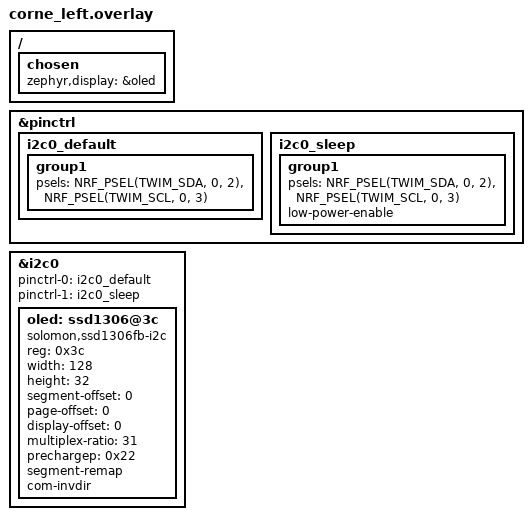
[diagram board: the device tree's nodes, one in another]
/ {
  chosen { zephyr,display = &oled; };
};

&pinctrl {
  i2c0_default: i2c0_default {
    group1 { psels = <NRF_PSEL(TWIM_SDA, 0, 2)>, <NRF_PSEL(TWIM_SCL, 0, 3)>; };
  };
  i2c0_sleep: i2c0_sleep {
    group1 { psels = <NRF_PSEL(TWIM_SDA, 0, 2)>, <NRF_PSEL(TWIM_SCL, 0, 3)>; low-power-enable; };
  };
};

&i2c0 {
  status = "okay";
  pinctrl-0 = <&i2c0_default>;
  pinctrl-1 = <&i2c0_sleep>;
  pinctrl-names = "default", "sleep";

  oled: ssd1306@3c {
    compatible = "solomon,ssd1306fb-i2c";
    reg = <0x3c>;
    status = "okay";
    width = <128>;
    height = <32>;
    segment-offset = <0>;
    page-offset = <0>;
    display-offset = <0>;
    multiplex-ratio = <31>;
    prechargep = <0x22>;
    segment-remap;
    com-invdir;
  };
};
